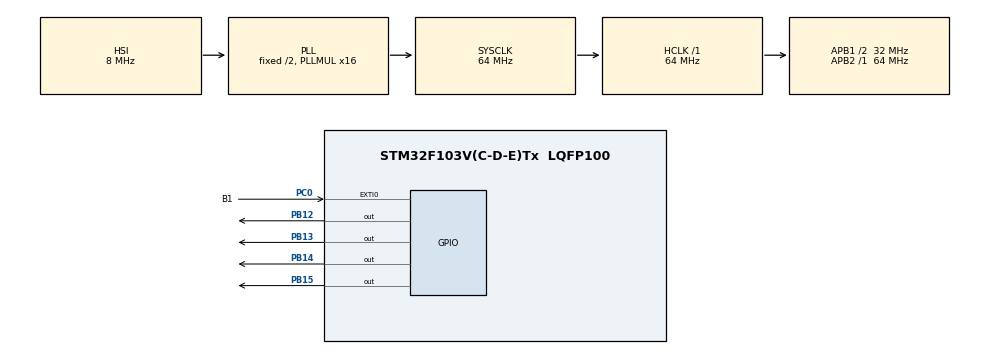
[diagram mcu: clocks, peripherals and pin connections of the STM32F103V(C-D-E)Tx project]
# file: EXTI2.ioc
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Mcu.Family=STM32F1
Mcu.Name=STM32F103V(C-D-E)Tx
Mcu.Package=LQFP100
NVIC.EXTI0_IRQn=true\:0\:0\:false\:false\:true\:true\:true
NVIC.PriorityGroup=NVIC_PRIORITYGROUP_4
PB12.Signal=GPIO_Output
PB13.Signal=GPIO_Output
PB14.Signal=GPIO_Output
PB15.Signal=GPIO_Output
PC0.GPIO_Label=B1
PC0.GPIO_ModeDefaultEXTI=GPIO_MODE_IT_FALLING
PC0.Signal=GPXTI0
ProjectManager.HeapSize=0x200
ProjectManager.StackSize=0x400
ProjectManager.TargetToolchain=STM32CubeIDE
RCC.AHBFreq_Value=64000000
RCC.APB1CLKDivider=RCC_HCLK_DIV2
RCC.APB1Freq_Value=32000000
RCC.APB1TimFreq_Value=64000000
RCC.APB2Freq_Value=64000000
RCC.APB2TimFreq_Value=64000000
RCC.HCLKFreq_Value=64000000
RCC.PLLMUL=RCC_PLL_MUL16
RCC.SYSCLKFreq_VALUE=64000000
RCC.SYSCLKSource=RCC_SYSCLKSOURCE_PLLCLK
RCC.USBFreq_Value=64000000
VP_SYS_VS_ND.Mode=No_Debug
board=custom

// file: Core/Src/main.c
/* USER CODE BEGIN Header */
/**
  ******************************************************************************
  * @file           : main.c
  * @brief          : Main program body
  ******************************************************************************
  * @attention
  *
  * <h2><center>&copy; Copyright (c) 2020 STMicroelectronics.
  * All rights reserved.</center></h2>
  *
  * This software component is licensed by ST under BSD 3-Clause license,
  * the "License"; You may not use this file except in compliance with the
  * License. You may obtain a copy of the License at:
  *                        opensource.org/licenses/BSD-3-Clause
  *
  ******************************************************************************
  */
/* USER CODE END Header */

#include "main.h"

void SystemClock_Config(void);
static void MX_GPIO_Init(void);

int main(void)
{

  /* MCU Configuration--------------------------------------------------------*/

  /* Reset of all peripherals, Initializes the Flash interface and the Systick. */
  HAL_Init();

  /* Configure the system clock */
  SystemClock_Config();

  /* Initialize all configured peripherals */
  MX_GPIO_Init();

  /* Infinite loop */
  while (1)
  {

  }
}

void SystemClock_Config(void)
{
  RCC_OscInitTypeDef RCC_OscInitStruct = {0};
  RCC_ClkInitTypeDef RCC_ClkInitStruct = {0};

  /** Initializes the CPU, AHB and APB busses clocks
  */
  RCC_OscInitStruct.OscillatorType = RCC_OSCILLATORTYPE_HSI;
  RCC_OscInitStruct.HSIState = RCC_HSI_ON;
  RCC_OscInitStruct.HSICalibrationValue = RCC_HSICALIBRATION_DEFAULT;
  RCC_OscInitStruct.PLL.PLLState = RCC_PLL_ON;
  RCC_OscInitStruct.PLL.PLLSource = RCC_PLLSOURCE_HSI_DIV2;
  RCC_OscInitStruct.PLL.PLLMUL = RCC_PLL_MUL16;
  if (HAL_RCC_OscConfig(&RCC_OscInitStruct) != HAL_OK)
  {
    Error_Handler();
  }
  /** Initializes the CPU, AHB and APB busses clocks
  */
  RCC_ClkInitStruct.ClockType = RCC_CLOCKTYPE_HCLK|RCC_CLOCKTYPE_SYSCLK
                              |RCC_CLOCKTYPE_PCLK1|RCC_CLOCKTYPE_PCLK2;
  RCC_ClkInitStruct.SYSCLKSource = RCC_SYSCLKSOURCE_PLLCLK;
  RCC_ClkInitStruct.AHBCLKDivider = RCC_SYSCLK_DIV1;
  RCC_ClkInitStruct.APB1CLKDivider = RCC_HCLK_DIV2;
  RCC_ClkInitStruct.APB2CLKDivider = RCC_HCLK_DIV1;

  if (HAL_RCC_ClockConfig(&RCC_ClkInitStruct, FLASH_LATENCY_2) != HAL_OK)
  {
    Error_Handler();
  }
}

static void MX_GPIO_Init(void)
{
  GPIO_InitTypeDef GPIO_InitStruct = {0};

  /* GPIO Ports Clock Enable */
  __HAL_RCC_GPIOC_CLK_ENABLE();
  __HAL_RCC_GPIOB_CLK_ENABLE();

  /*Configure GPIO pin Output Level */
  HAL_GPIO_WritePin(GPIOB, GPIO_PIN_12|GPIO_PIN_13|GPIO_PIN_14|GPIO_PIN_15, GPIO_PIN_RESET);

  /*Configure GPIO pin : B1_Pin */
  GPIO_InitStruct.Pin = B1_Pin;
  GPIO_InitStruct.Mode = GPIO_MODE_IT_FALLING;
  GPIO_InitStruct.Pull = GPIO_NOPULL;
  HAL_GPIO_Init(B1_GPIO_Port, &GPIO_InitStruct);

  /*Configure GPIO pins : PB12 PB13 PB14 PB15 */
  GPIO_InitStruct.Pin = GPIO_PIN_12|GPIO_PIN_13|GPIO_PIN_14|GPIO_PIN_15;
  GPIO_InitStruct.Mode = GPIO_MODE_OUTPUT_PP;
  GPIO_InitStruct.Pull = GPIO_NOPULL;
  GPIO_InitStruct.Speed = GPIO_SPEED_FREQ_LOW;
  HAL_GPIO_Init(GPIOB, &GPIO_InitStruct);

  /* EXTI interrupt init*/
  HAL_NVIC_SetPriority(EXTI0_IRQn, 0, 0);
  HAL_NVIC_EnableIRQ(EXTI0_IRQn);

}

/* USER CODE BEGIN 4 */
void HAL_GPIO_EXTI_Callback(uint16_t GPIO_Pin)
{
  switch(GPIO_Pin)
  {
  case B1_Pin:
	  HAL_GPIO_TogglePin(GPIOB, GPIO_PIN_12);
	  HAL_GPIO_TogglePin(GPIOB, GPIO_PIN_13);
	  HAL_GPIO_TogglePin(GPIOB, GPIO_PIN_14);
	  HAL_GPIO_TogglePin(GPIOB, GPIO_PIN_15);
	  break;

  default:
	  ;
  }
}

/* USER CODE END 4 */

void Error_Handler(void)
{
}

/************************ (C) COPYRIGHT STMicroelectronics *****END OF FILE****/
